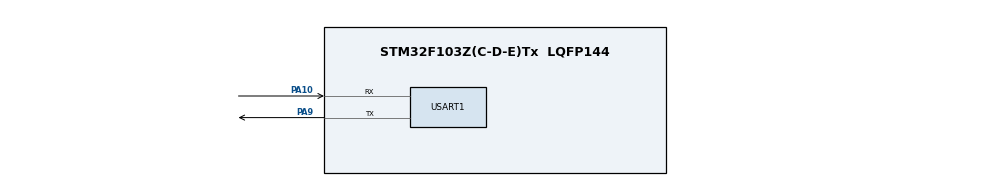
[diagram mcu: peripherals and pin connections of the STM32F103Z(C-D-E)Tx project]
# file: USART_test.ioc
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Mcu.Family=STM32F1
Mcu.Name=STM32F103Z(C-D-E)Tx
Mcu.Package=LQFP144
NVIC.PriorityGroup=NVIC_PRIORITYGROUP_4
NVIC.USART1_IRQn=true\:0\:0\:false\:false\:true\:true\:true
OSC_IN.Mode=HSE-External-Oscillator
OSC_IN.Signal=RCC_OSC_IN
OSC_OUT.Mode=HSE-External-Oscillator
OSC_OUT.Signal=RCC_OSC_OUT
PA10.Mode=Asynchronous
PA10.Signal=USART1_RX
PA13.Mode=Serial_Wire
PA13.Signal=SYS_JTMS-SWDIO
PA14.Mode=Serial_Wire
PA14.Signal=SYS_JTCK-SWCLK
PA9.Mode=Asynchronous
PA9.Signal=USART1_TX
ProjectManager.HeapSize=0x200
ProjectManager.StackSize=0x400
ProjectManager.TargetToolchain=TrueSTUDIO
RCC.APB1Freq_Value=8000000
RCC.APB2Freq_Value=8000000
USART1.VirtualMode=VM_ASYNC
board=custom

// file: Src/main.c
/* USER CODE BEGIN Header */
/**
  ******************************************************************************
  * @file           : main.c
  * @brief          : Main program body
  ******************************************************************************
  * @attention
  *
  * <h2><center>&copy; Copyright (c) 2020 STMicroelectronics.
  * All rights reserved.</center></h2>
  *
  * This software component is licensed by ST under BSD 3-Clause license,
  * the "License"; You may not use this file except in compliance with the
  * License. You may obtain a copy of the License at:
  *                        opensource.org/licenses/BSD-3-Clause
  *
  ******************************************************************************
  */
/* USER CODE END Header */

#include "main.h"
#include "usart.h"
#include "gpio.h"

/* USER CODE BEGIN Includes */
#include"string.h"
/* USER CODE END Includes */

/* USER CODE BEGIN PD */
#define BUFF_Size 256		//Max bytes received
/* USER CODE END PD */

/* USER CODE BEGIN PV */
char RX_BUFFER[BUFF_Size];   //Receive Data
uint8_t aRX_BUFFER;          //Receive Interrupt Buffer
uint8_t UART1_Rx_Cnt = 0;    //Receive Buffer Count
/* USER CODE END PV */

void SystemClock_Config(void);

int main(void)
{

  /* MCU Configuration--------------------------------------------------------*/

  /* Reset of all peripherals, Initializes the Flash interface and the Systick. */
  HAL_Init();

  /* Configure the system clock */
  SystemClock_Config();

  /* Initialize all configured peripherals */
  MX_GPIO_Init();
  MX_USART1_UART_Init();
  /* USER CODE BEGIN 2 */
  HAL_UART_Receive_IT(&huart1,(uint8_t*)&aRX_BUFFER,1);
  /* USER CODE END 2 */

  /* Infinite loop */
  while (1)
  {

  }
}

void SystemClock_Config(void)
{
  RCC_OscInitTypeDef RCC_OscInitStruct = {0};
  RCC_ClkInitTypeDef RCC_ClkInitStruct = {0};

  /** Initializes the CPU, AHB and APB busses clocks
  */
  RCC_OscInitStruct.OscillatorType = RCC_OSCILLATORTYPE_HSI;
  RCC_OscInitStruct.HSIState = RCC_HSI_ON;
  RCC_OscInitStruct.HSICalibrationValue = RCC_HSICALIBRATION_DEFAULT;
  RCC_OscInitStruct.PLL.PLLState = RCC_PLL_NONE;
  if (HAL_RCC_OscConfig(&RCC_OscInitStruct) != HAL_OK)
  {
    Error_Handler();
  }
  /** Initializes the CPU, AHB and APB busses clocks
  */
  RCC_ClkInitStruct.ClockType = RCC_CLOCKTYPE_HCLK|RCC_CLOCKTYPE_SYSCLK
                              |RCC_CLOCKTYPE_PCLK1|RCC_CLOCKTYPE_PCLK2;
  RCC_ClkInitStruct.SYSCLKSource = RCC_SYSCLKSOURCE_HSI;
  RCC_ClkInitStruct.AHBCLKDivider = RCC_SYSCLK_DIV1;
  RCC_ClkInitStruct.APB1CLKDivider = RCC_HCLK_DIV1;
  RCC_ClkInitStruct.APB2CLKDivider = RCC_HCLK_DIV1;

  if (HAL_RCC_ClockConfig(&RCC_ClkInitStruct, FLASH_LATENCY_0) != HAL_OK)
  {
    Error_Handler();
  }
}

/* USER CODE BEGIN 4 */
void HAL_UART_RxCpltCallback(UART_HandleTypeDef *huart)
{
	UNUSED(huart);
	if (UART1_Rx_Cnt >=255)
	{
		UART1_Rx_Cnt = 0;
		memset(RX_BUFFER,0x00,sizeof(RX_BUFFER));
		HAL_UART_Transmit(&huart1,(uint8_t *)"数据溢出",UART1_Rx_Cnt,0xFFFF);
	}
	else
	{
		RX_BUFFER[UART1_Rx_Cnt ++] = aRX_BUFFER;
		if((RX_BUFFER[UART1_Rx_Cnt - 1] == 0x0A)&&(RX_BUFFER[UART1_Rx_Cnt - 2] == 0x0D))
		{
			HAL_UART_Transmit(&huart1,(uint8_t *)&RX_BUFFER,UART1_Rx_Cnt,0xFFFF);
			while(HAL_UART_GetState(&huart1) == HAL_UART_STATE_BUSY_TX);
			UART1_Rx_Cnt = 0;
			memset(RX_BUFFER,0x00,sizeof(RX_BUFFER));
		}
	}
	HAL_UART_Receive_IT(&huart1,(uint8_t *)&aRX_BUFFER,1);
}
/* USER CODE END 4 */

void Error_Handler(void)
{
}

/************************ (C) COPYRIGHT STMicroelectronics *****END OF FILE****/
